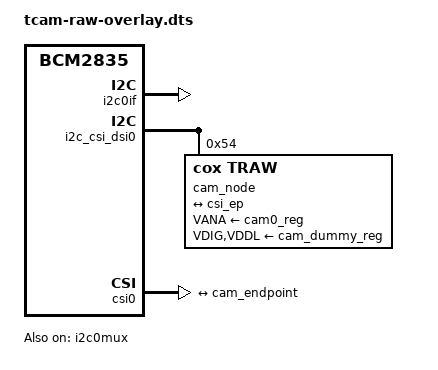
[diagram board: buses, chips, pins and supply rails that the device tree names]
// SPDX-License-Identifier: GPL-2.0-only
// Definitions for Thermal camera raw module on VC I2C bus
/dts-v1/;
/plugin/;

/{
	compatible = "brcm,bcm2835";

	fragment@0 {
		target = <&i2c0if>;
		__overlay__ {
			status = "okay";
		};
	};

	clk_frag: fragment@1 {
		target = <&cam0_clk>;
		__overlay__ {
			clock-frequency = <24000000>;
			status = "okay";
		};
	};

	fragment@2 {
		target = <&i2c0mux>;
		__overlay__ {
			status = "okay";
		};
	};

	i2c_frag: fragment@100 {
		target = <&i2c_csi_dsi0>;
		__overlay__ {
			#address-cells = <1>;
			#size-cells = <0>;
			status = "okay";

			cam_node: tcamraw@54 {
				compatible = "cox,traw";
				reg = <0x54>;
				status = "okay";

				clocks = <&cam0_clk>;
				clock-names = "xclk";

				VANA-supply = <&cam0_reg>;	/* 2.8v */
				VDIG-supply = <&cam_dummy_reg>;	/* 1.8v */
				VDDL-supply = <&cam_dummy_reg>;	/* 1.2v */

				rotation = <0>;
				orientation = <2>;

				port {
					cam_endpoint: endpoint {
						remote-endpoint = <&csi_ep>;
						clock-lanes = <0>;
						data-lanes = <1 2>;
						clock-noncontinuous;
						link-frequencies =
							/bits/ 64 <456000000>;
					};
				};
			};
		};
	};

	csi_frag: fragment@101 {
		target = <&csi0>;
		csi: __overlay__ {
			status = "okay";

			port {
				csi_ep: endpoint {
					remote-endpoint = <&cam_endpoint>;
					clock-lanes = <0>;
					data-lanes = <1 2>;
					clock-noncontinuous;
				};
			};
		};
	};

	fragment@102 {
		target = <&csi0>;
		__dormant__ {
			compatible = "brcm,bcm2835-unicam-legacy";
		};
	};

	__overrides__ {
		media-controller = <0>,"!102";
		rotation = <&cam_node>,"rotation:0";
		orientation = <&cam_node>,"orientation:0";
	};
};

